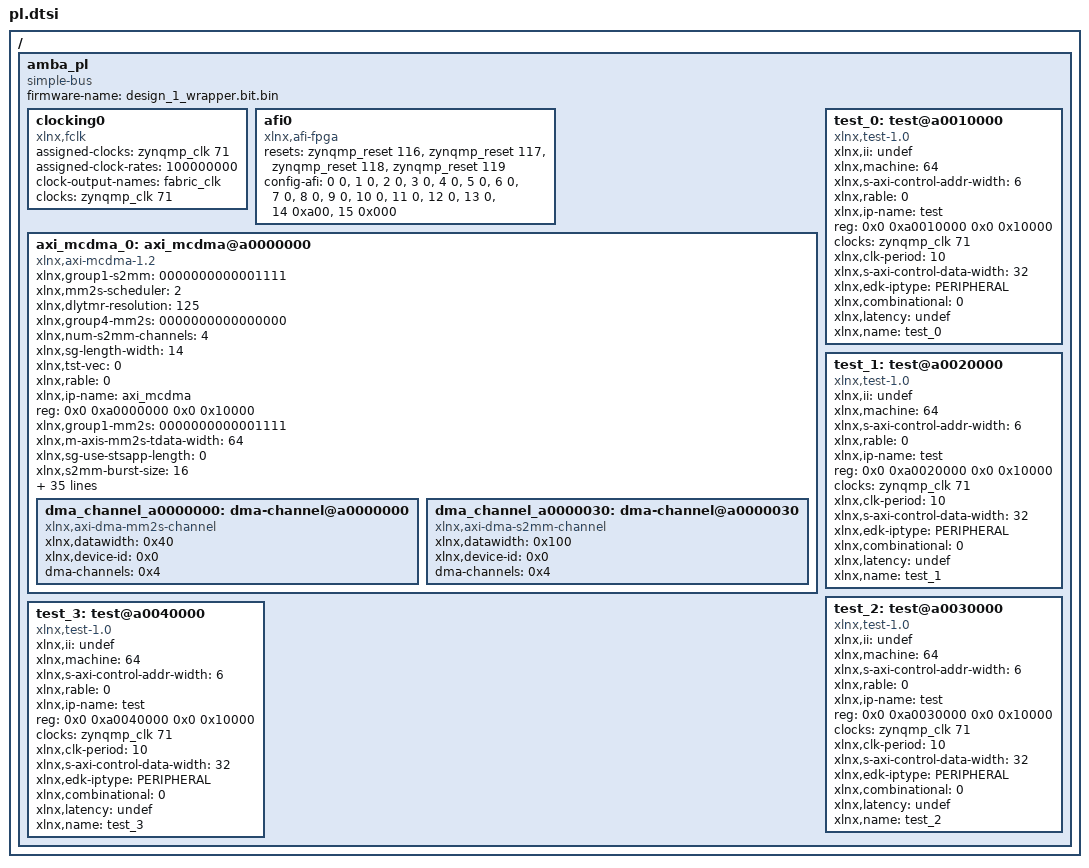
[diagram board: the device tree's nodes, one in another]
/ {
	amba_pl: amba_pl {
		ranges;
		compatible = "simple-bus";
		#address-cells = <2>;
		#size-cells = <2>;
		firmware-name = "design_1_wrapper.bit.bin";
		clocking0: clocking0 {
			compatible = "xlnx,fclk";
			status = "okay";
			assigned-clocks = <&zynqmp_clk 71>;
			assigned-clock-rates = <100000000>;
			#clock-cells = <0>;
			clock-output-names = "fabric_clk";
			clocks = <&zynqmp_clk 71>;
		};
		afi0: afi0 {
			status = "okay";
			compatible = "xlnx,afi-fpga";
			resets = <&zynqmp_reset 116>, <&zynqmp_reset 117>, <&zynqmp_reset 118>, <&zynqmp_reset 119>;
			config-afi = < 0 0>, <1 0>, <2 0>, <3 0>, <4 0>, <5 0>, <6 0>, <7 0>, <8 0>, <9 0>, <10 0>, <11 0>, <12 0>, <13 0>, <14 0xa00>, <15 0x000>;
		};
		axi_mcdma_0: axi_mcdma@a0000000 {
			xlnx,group1-s2mm = <0000000000001111>;
			xlnx,mm2s-scheduler = <2>;
			xlnx,dlytmr-resolution = <125>;
			xlnx,group4-mm2s = <0000000000000000>;
			xlnx,num-s2mm-channels = <4>;
			xlnx,sg-length-width = <14>;
			xlnx,tst-vec = <0>;
			xlnx,rable = <0>;
			xlnx,ip-name = "axi_mcdma";
			reg = <0x0 0xa0000000 0x0 0x10000>;
			xlnx,group1-mm2s = <0000000000001111>;
			xlnx,m-axis-mm2s-tdata-width = <64>;
			xlnx,sg-use-stsapp-length = <0>;
			xlnx,s2mm-burst-size = <16>;
			xlnx,num-mm2s-channels = <4>;
			xlnx,group6-s2mm = <0000000000000000>;
			xlnx,enable-single-intr = <0>;
			xlnx,enable-multi-intr = <1>;
			compatible = "xlnx,axi-mcdma-1.2" , "xlnx,axi-mcdma-1.00.a";
			xlnx,group3-s2mm = <0000000000000000>;
			xlnx,mm2s-burst-size = <8>;
			xlnx,enable-multi-ch-reset = <0>;
			xlnx,group6-mm2s = <0000000000000000>;
			xlnx,include-s2mm-dre = <0>;
			xlnx,group3-mm2s = <0000000000000000>;
			xlnx,m-axi-s2mm-data-width = <256>;
			xlnx,support-cyclic-bd = <0>;
			status = "okay";
			xlnx,include-mm2s-dre = <0>;
			xlnx,name = "axi_mcdma_0";
			xlnx,m-axi-mm2s-data-width = <64>;
			xlnx,ethernet-dma = <0>;
			xlnx,group5-s2mm = <0000000000000000>;
			xlnx,include-s2mm-sf = <1>;
			xlnx,addr-width = <32>;
			xlnx,include-s2mm = <1>;
			xlnx,single-interface = <0>;
			clocks = <&zynqmp_clk 71>, <&zynqmp_clk 71>;
			xlnx,s-axis-s2mm-tdata-width = <256>;
			xlnx,addrwidth = /bits/ 8 <0x20>;
			xlnx,group2-s2mm = <0000000000000000>;
			xlnx,edk-iptype = "PERIPHERAL";
			xlnx,group5-mm2s = <0000000000000000>;
			xlnx,include-mm2s-sf = <1>;
			clock-names = "s_axi_aclk" , "s_axi_lite_aclk";
			xlnx,include-mm2s = <1>;
			xlnx,s2mm-data-width = <0x100>;
			xlnx,group2-mm2s = <0000000000000000>;
			xlnx,prmry-is-aclk-async = <0>;
			#dma-cells = <1>;
			xlnx,sg-include-stscntrl-strm = <0>;
			xlnx,mm2s-data-width = <0x40>;
			xlnx,group4-s2mm = <0000000000000000>;
			dma_channel_a0000000: dma-channel@a0000000 {
				xlnx,datawidth = <0x40>;
				xlnx,device-id = <0x0>;
				compatible = "xlnx,axi-dma-mm2s-channel";
				dma-channels = <0x4>;
			};
			dma_channel_a0000030: dma-channel@a0000030 {
				xlnx,datawidth = <0x100>;
				xlnx,device-id = <0x0>;
				compatible = "xlnx,axi-dma-s2mm-channel";
				dma-channels = <0x4>;
			};
		};
		test_0: test@a0010000 {
			compatible = "xlnx,test-1.0";
			xlnx,ii = "undef";
			xlnx,machine = <64>;
			xlnx,s-axi-control-addr-width = <6>;
			xlnx,rable = <0>;
			xlnx,ip-name = "test";
			reg = <0x0 0xa0010000 0x0 0x10000>;
			clocks = <&zynqmp_clk 71>;
			xlnx,clk-period = <10>;
			xlnx,s-axi-control-data-width = <32>;
			xlnx,edk-iptype = "PERIPHERAL";
			status = "okay";
			clock-names = "ap_clk";
			xlnx,combinational = <0>;
			xlnx,latency = "undef";
			xlnx,name = "test_0";
		};
		test_1: test@a0020000 {
			compatible = "xlnx,test-1.0";
			xlnx,ii = "undef";
			xlnx,machine = <64>;
			xlnx,s-axi-control-addr-width = <6>;
			xlnx,rable = <0>;
			xlnx,ip-name = "test";
			reg = <0x0 0xa0020000 0x0 0x10000>;
			clocks = <&zynqmp_clk 71>;
			xlnx,clk-period = <10>;
			xlnx,s-axi-control-data-width = <32>;
			xlnx,edk-iptype = "PERIPHERAL";
			status = "okay";
			clock-names = "ap_clk";
			xlnx,combinational = <0>;
			xlnx,latency = "undef";
			xlnx,name = "test_1";
		};
		test_2: test@a0030000 {
			compatible = "xlnx,test-1.0";
			xlnx,ii = "undef";
			xlnx,machine = <64>;
			xlnx,s-axi-control-addr-width = <6>;
			xlnx,rable = <0>;
			xlnx,ip-name = "test";
			reg = <0x0 0xa0030000 0x0 0x10000>;
			clocks = <&zynqmp_clk 71>;
			xlnx,clk-period = <10>;
			xlnx,s-axi-control-data-width = <32>;
			xlnx,edk-iptype = "PERIPHERAL";
			status = "okay";
			clock-names = "ap_clk";
			xlnx,combinational = <0>;
			xlnx,latency = "undef";
			xlnx,name = "test_2";
		};
		test_3: test@a0040000 {
			compatible = "xlnx,test-1.0";
			xlnx,ii = "undef";
			xlnx,machine = <64>;
			xlnx,s-axi-control-addr-width = <6>;
			xlnx,rable = <0>;
			xlnx,ip-name = "test";
			reg = <0x0 0xa0040000 0x0 0x10000>;
			clocks = <&zynqmp_clk 71>;
			xlnx,clk-period = <10>;
			xlnx,s-axi-control-data-width = <32>;
			xlnx,edk-iptype = "PERIPHERAL";
			status = "okay";
			clock-names = "ap_clk";
			xlnx,combinational = <0>;
			xlnx,latency = "undef";
			xlnx,name = "test_3";
		};
	};
};
